# EFM32GG12B390F1024GL112 register map
File version: 3.0.0
CPU: CM4 r0p1, little endian, MPU, FPU, 3 interrupt priority bits
Registers are 32-bit, read-write, reset 0x0 unless marked. A register's access mark holds for its fields unless they carry their own. Offsets are from the block's base; [hi:lo] are bit positions; {n}, {i} and the like mark numbered series.

## QSPI0
Base 0x4001C400
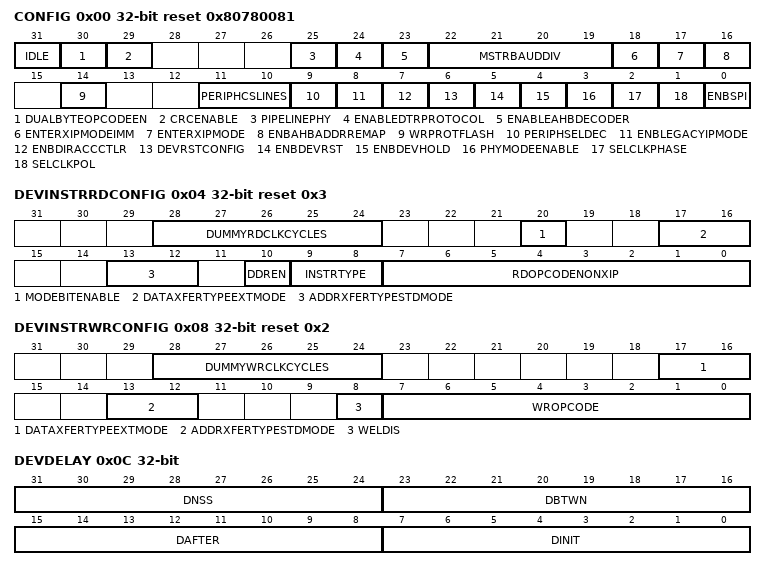
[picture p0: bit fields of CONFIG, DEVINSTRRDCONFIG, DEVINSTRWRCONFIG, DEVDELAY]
0x00 CONFIG reset 0x80780081 — Octal-SPI Configuration Register
  [31] IDLE ro — Serial Interface and Low Level SPI Pipeline is IDLE
  [30] DUALBYTEOPCODEEN — Dual-byte Opcode Mode Enable Bit
  [29] CRCENABLE — CRC Enable Bit
  [25] PIPELINEPHY — Pipeline PHY Mode Enable
  [24] ENABLEDTRPROTOCOL
  [23] ENABLEAHBDECODER — Enable Address Decoder
  [22:19] MSTRBAUDDIV — Master Mode Baud Rate Divisor
  [18] ENTERXIPMODEIMM — Enter XIP Mode Immediately
  [17] ENTERXIPMODE — Enter XIP Mode on Next READ
  [16] ENBAHBADDRREMAP — Enable Address Remapping
  [14] WRPROTFLASH — Write Protect Flash Pin
  [11:10] PERIPHCSLINES — Peripheral Chip Select Lines
  [9] PERIPHSELDEC — Peripheral Select Decode
  [8] ENBLEGACYIPMODE — Legacy IP Mode Enable
  [7] ENBDIRACCCTLR — Enable Direct Access Controller
  [6] DEVRSTCONFIG — Device Reset Configuration
  [5] ENBDEVRST — Enable Device Reset
  [4] ENBDEVHOLD — Enable Device Hold
  [3] PHYMODEENABLE
  [2] SELCLKPHASE — Clock Phase, CPHA
  [1] SELCLKPOL — Clock Polarity, CPOL
  [0] ENBSPI — QSPI Enable
0x04 DEVINSTRRDCONFIG reset 0x3 — Device Read Instruction Configuration Register
  [28:24] DUMMYRDCLKCYCLES — Dummy Read Clock Cycles
  [20] MODEBITENABLE
  [17:16] DATAXFERTYPEEXTMODE — Data Transfer Type for Standard SPI Modes
  [13:12] ADDRXFERTYPESTDMODE — Address Transfer Type for Standard SPI Modes
  [10] DDREN — DDR Enable
  [9:8] INSTRTYPE — Instruction Type
  [7:0] RDOPCODENONXIP — Read Opcode in Non-XIP Mode
0x08 DEVINSTRWRCONFIG reset 0x2 — Device Write Instruction Configuration Register
  [28:24] DUMMYWRCLKCYCLES — Dummy Write Clock Cycles
  [17:16] DATAXFERTYPEEXTMODE — Data Transfer Type for Standard SPI Modes
  [13:12] ADDRXFERTYPESTDMODE — Address Transfer Type for Standard SPI Modes
  [8] WELDIS — WEL Disable
  [7:0] WROPCODE — Write Opcode
0x0C DEVDELAY — Device Delay Register
  [31:24] DNSS — Clock Delay for Chip Select Deassert
  [23:16] DBTWN — Clock Delay Between Two Chip Selects
  [15:8] DAFTER — Clock Delay for Last Transaction Bit
  [7:0] DINIT — Clock Delay for CS
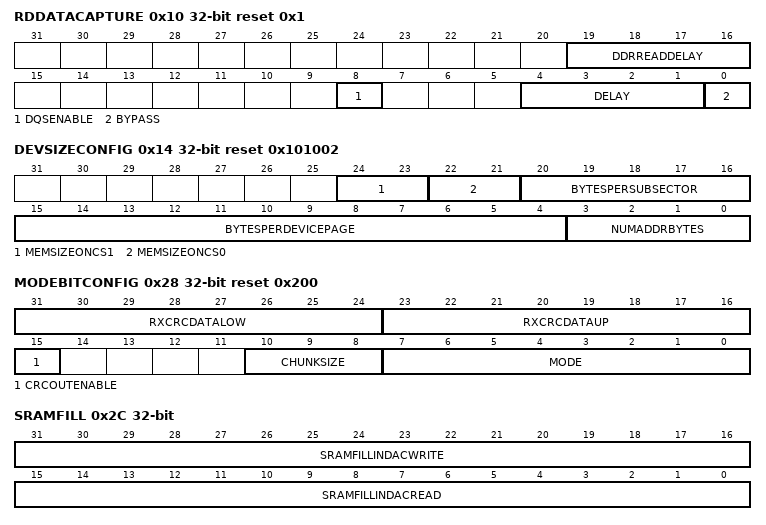
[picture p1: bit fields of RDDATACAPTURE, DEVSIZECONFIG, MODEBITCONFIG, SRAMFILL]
0x10 RDDATACAPTURE reset 0x1 — Read Data Capture Register
  [19:16] DDRREADDELAY
  [8] DQSENABLE — DQS Enable Bit
  [4:1] DELAY — Read Delay
  [0] BYPASS — Bypass the Adapted Loopback Clock Circuit
0x14 DEVSIZECONFIG reset 0x101002 — Device Size Configuration Register
  [24:23] MEMSIZEONCS1 — Size of Flash Device Connected to CS[1] Pin
  [22:21] MEMSIZEONCS0 — Size of Flash Device Connected to CS[0] Pin
  [20:16] BYTESPERSUBSECTOR — Number of Bytes Per Block
  [15:4] BYTESPERDEVICEPAGE — Number of Bytes Per Device Page
  [3:0] NUMADDRBYTES — Number of Address Bytes
0x18 SRAMPARTITIONCFG reset 0x80 — SRAM Partition Configuration Register
  [7:0] ADDR — Indirect Read Partition Size
0x1C INDAHBADDRTRIGGER — Indirect Address Trigger Register
  [31:0] ADDR
0x24 REMAPADDR — Remap Address Register
  [31:0] VALUE — Remap Address Value
0x28 MODEBITCONFIG reset 0x200 — Mode Bit Configuration Register
  [31:24] RXCRCDATALOW ro — RX CRC Data (lower)
  [23:16] RXCRCDATAUP ro — RX CRC Data (upper)
  [15] CRCOUTENABLE — CRC# Output Enable Bit
  [10:8] CHUNKSIZE
  [7:0] MODE — Mode Bits
0x2C SRAMFILL ro
  [31:16] SRAMFILLINDACWRITE — SRAM Fill Level (Indirect Write Partition)
  [15:0] SRAMFILLINDACREAD — SRAM Fill Level (Indirect Read Partition)
0x30 TXTHRESH reset 0x1 — TX Threshold Register
  [4:0] LEVEL — Threshold Level
0x34 RXTHRESH reset 0x1 — RX Threshold Register
  [4:0] LEVEL — Threshold Level
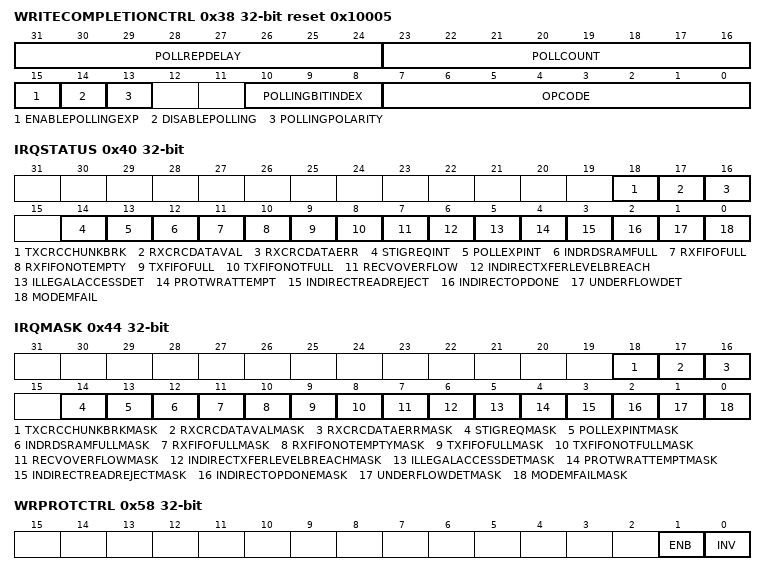
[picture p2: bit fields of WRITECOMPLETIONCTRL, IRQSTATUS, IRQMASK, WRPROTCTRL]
0x38 WRITECOMPLETIONCTRL reset 0x10005 — Write Completion Control Register
  [31:24] POLLREPDELAY — Poll Repetition Delay
  [23:16] POLLCOUNT
  [15] ENABLEPOLLINGEXP — Enable Polling Expiration
  [14] DISABLEPOLLING
  [13] POLLINGPOLARITY
  [10:8] POLLINGBITINDEX
  [7:0] OPCODE
0x3C NOOFPOLLSBEFEXP reset 0xFFFFFFFF — Polling Expiration Register
  [31:0] NOOFPOLLSBEFEXP — Number of Polls Cycles Before Expiration
0x40 IRQSTATUS — Interrupt Status Register
  [18] TXCRCCHUNKBRK — TX CRC Chunk Was Broken
  [17] RXCRCDATAVAL — RX CRC Data Valid
  [16] RXCRCDATAERR — RX CRC Data Error
  [14] STIGREQINT — The Controller is Ready for Getting Another STIG Request
  [13] POLLEXPINT — The Maximum Number of Programmed Polls Cycles is Expired
  [12] INDRDSRAMFULL — Indirect Read Partition Overflow
  [11] RXFIFOFULL — Small RX FIFO Full
  [10] RXFIFONOTEMPTY — Small RX FIFO Not Empty
  [9] TXFIFOFULL — Small TX FIFO Full
  [8] TXFIFONOTFULL — Small TX FIFO Not Full
  [7] RECVOVERFLOW — Receive Overflow
  [6] INDIRECTXFERLEVELBREACH — Indirect Transfer Watermark Level Breached
  [5] ILLEGALACCESSDET — Illegal Memory Access Has Been Detected
  [4] PROTWRATTEMPT — Write to Protected Area Was Attempted and Rejected
  [3] INDIRECTREADREJECT — Indirect Operation Was Requested but Could Not Be Accepted
  [2] INDIRECTOPDONE — Indirect Operation Complete
  [1] UNDERFLOWDET — Underflow Detected
  [0] MODEMFAIL — Mode M Failure
0x44 IRQMASK — Interrupt Mask
  [18] TXCRCCHUNKBRKMASK — TX CRC Chunk Was Broken Mask
  [17] RXCRCDATAVALMASK — RX CRC Data Valid Mask
  [16] RXCRCDATAERRMASK — RX CRC Data Error Mask
  [14] STIGREQMASK — STIG Request Completion Mask
  [13] POLLEXPINTMASK — Polling Expiration Detected Mask
  [12] INDRDSRAMFULLMASK — Indirect Read Partition Overflow Mask
  [11] RXFIFOFULLMASK — Small RX FIFO Full Mask
  [10] RXFIFONOTEMPTYMASK — Small RX FIFO Not Empty Mask
  [9] TXFIFOFULLMASK — Small TX FIFO Full Mask
  [8] TXFIFONOTFULLMASK — Small TX FIFO Not Full Mask
  [7] RECVOVERFLOWMASK — Receive Overflow Mask
  [6] INDIRECTXFERLEVELBREACHMASK — Transfer Watermark Breach Mask
  [5] ILLEGALACCESSDETMASK — Illegal Access Detected Mask
  [4] PROTWRATTEMPTMASK — Protected Area Write Attempt Mask
  [3] INDIRECTREADREJECTMASK
  [2] INDIRECTOPDONEMASK — Indirect Complete Mask
  [1] UNDERFLOWDETMASK — Underflow Detected Mask
  [0] MODEMFAILMASK — Mode M Failure Mask
0x50 LOWERWRPROT — Lower Write Protection Register
  [31:0] SUBSECTOR — Lower Block Number
0x54 UPPERWRPROT — Upper Write Protection Register
  [31:0] SUBSECTOR — Upper Block Number
0x58 WRPROTCTRL — Write Protection Control Register
  [1] ENB — Write Protection Enable Bit
  [0] INV — Write Protection Inversion Bit
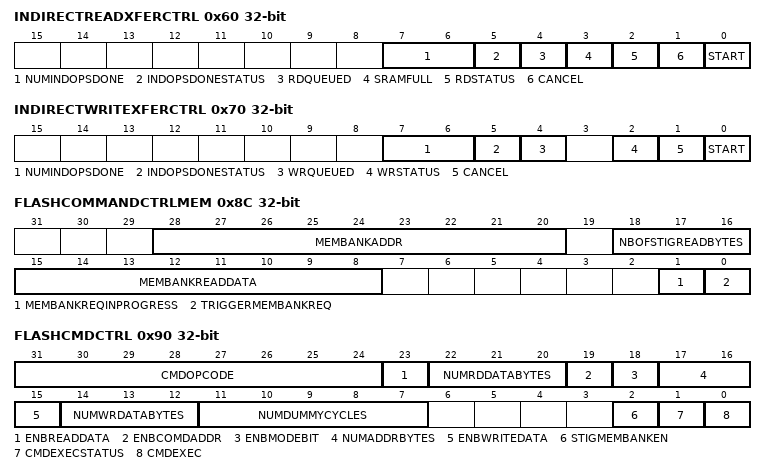
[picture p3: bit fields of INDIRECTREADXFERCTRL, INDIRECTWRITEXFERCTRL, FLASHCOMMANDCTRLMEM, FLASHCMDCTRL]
0x60 INDIRECTREADXFERCTRL — Indirect Read Transfer Control Register
  [7:6] NUMINDOPSDONE ro — Number Indirect Operations Done
  [5] INDOPSDONESTATUS — Indirect Completion Status
  [4] RDQUEUED ro — Two Indirect Read Operations Have Been Queued
  [3] SRAMFULL
  [2] RDSTATUS ro — Indirect Read Status
  [1] CANCEL wo — Cancel Indirect Read
  [0] START wo — Start Indirect Read
0x64 INDIRECTREADXFERWATERMARK — Indirect Read Transfer Watermark Register
  [31:0] LEVEL — Watermark Value
0x68 INDIRECTREADXFERSTART — Indirect Read Transfer Start Address Register
  [31:0] ADDR — Indirect Read Transfer Start Address
0x6C INDIRECTREADXFERNUMBYTES — Indirect Read Transfer Number Bytes Register
  [31:0] VALUE — Indirect Read Transfer Number Bytes
0x70 INDIRECTWRITEXFERCTRL — Indirect Write Transfer Control Register
  [7:6] NUMINDOPSDONE ro — Indirect Operations Done
  [5] INDOPSDONESTATUS — Indirect Completion Status
  [4] WRQUEUED ro — Two Indirect Write Operations Have Been Queued
  [2] WRSTATUS ro — Indirect Write Status
  [1] CANCEL wo — Cancel Indirect Write
  [0] START wo — Start Indirect Write
0x74 INDIRECTWRITEXFERWATERMARK reset 0xFFFFFFFF — Indirect Write Transfer Watermark Register
  [31:0] LEVEL — Watermark Value
0x78 INDIRECTWRITEXFERSTART — Indirect Write Transfer Start Address Register
  [31:0] ADDR — Start of Indirect Access
0x7C INDIRECTWRITEXFERNUMBYTES — Indirect Write Transfer Number Bytes Register
  [31:0] VALUE — Indirect Number of Bytes
0x80 INDIRECTTRIGGERADDRRANGE reset 0x4 — Indirect Trigger Address Range Register
  [3:0] INDRANGEWIDTH — Indirect Trigger Address Width
0x8C FLASHCOMMANDCTRLMEM — Flash Command Control Memory Register (STIG)
  [28:20] MEMBANKADDR — Memory Bank Address
  [18:16] NBOFSTIGREADBYTES — Number of Read Bytes for the Extended STIG
  [15:8] MEMBANKREADDATA ro — Last Requested Data From the STIG Memory Bank
  [1] MEMBANKREQINPROGRESS ro — Memory Bank Data Request in Progress
  [0] TRIGGERMEMBANKREQ wo — Trigger the Memory Bank Data Request
0x90 FLASHCMDCTRL — Flash Command Control Register (STIG)
  [31:24] CMDOPCODE — Command Opcode
  [23] ENBREADDATA — Read Data Enable
  [22:20] NUMRDDATABYTES — Number of Read Data Bytes
  [19] ENBCOMDADDR — Command Address Enable
  [18] ENBMODEBIT — Mode Bit Enable
  [17:16] NUMADDRBYTES — Number of Address Bytes
  [15] ENBWRITEDATA — Write Data Enable
  [14:12] NUMWRDATABYTES — Number of Write Data Bytes
  [11:7] NUMDUMMYCYCLES — Number of Dummy Cycles
  [2] STIGMEMBANKEN — STIG Memory Bank Enable Bit
  [1] CMDEXECSTATUS ro — Command Execution in Progress
  [0] CMDEXEC wo — Execute the Command
0x94 FLASHCMDADDR — Flash Command Address Register (STIG)
  [31:0] ADDR — Command Address
0xA0 FLASHRDDATALOWER ro — Flash Command Read Data Register (Lower) (STIG)
  [31:0] DATA — Read Data Lower
0xA4 FLASHRDDATAUPPER ro — Flash Command Read Data Register (Upper) (STIG)
  [31:0] DATA — Read Data Upper
0xA8 FLASHWRDATALOWER — Flash Command Write Data Register (Lower) (STIG)
  [31:0] DATA — Command Write Data Lower Byte
0xAC FLASHWRDATAUPPER — Flash Command Write Data Register (Upper) (STIG)
  [31:0] DATA — Command Write Data Upper Byte
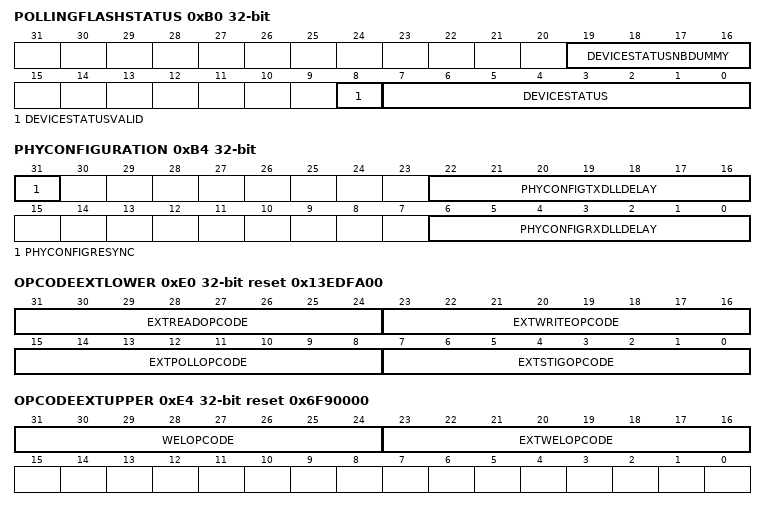
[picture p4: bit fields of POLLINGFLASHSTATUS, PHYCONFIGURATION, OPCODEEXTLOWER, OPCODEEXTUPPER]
0xB0 POLLINGFLASHSTATUS
  [19:16] DEVICESTATUSNBDUMMY — Auto-polling Dummy Cycles
  [8] DEVICESTATUSVALID ro
  [7:0] DEVICESTATUS ro
0xB4 PHYCONFIGURATION
  [31] PHYCONFIGRESYNC wo
  [22:16] PHYCONFIGTXDLLDELAY — TX DLL Delay
  [6:0] PHYCONFIGRXDLLDELAY — RX DLL Delay
0xE0 OPCODEEXTLOWER reset 0x13EDFA00 — Opcode Extension Register (Lower)
  [31:24] EXTREADOPCODE — Read Opcode Extension
  [23:16] EXTWRITEOPCODE — Write Opcode Extension
  [15:8] EXTPOLLOPCODE — Polling Opcode Extension
  [7:0] EXTSTIGOPCODE — STIG Opcode Extension
0xE4 OPCODEEXTUPPER reset 0x6F90000 — Opcode Extension Register (Upper)
  [31:24] WELOPCODE
  [23:16] EXTWELOPCODE — WEL Opcode Extension
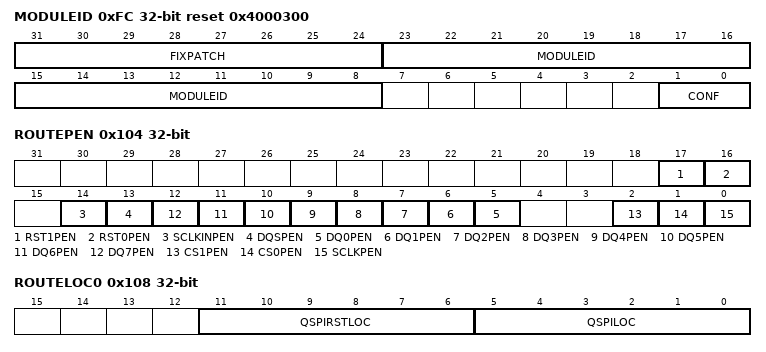
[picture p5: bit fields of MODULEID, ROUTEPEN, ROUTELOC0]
0xFC MODULEID ro reset 0x4000300
  [31:24] FIXPATCH — Fix/patch Number
  [23:8] MODULEID — Module/Revision ID Number
  [1:0] CONF — Configuration ID Number
0x104 ROUTEPEN — I/O Routing Pin Enable Register
  [17] RST1PEN — RST1 Pin Enable
  [16] RST0PEN — RST0 Pin Enable
  [14] SCLKINPEN — SCLKIN Pin Enable
  [13] DQSPEN — DQS Pin Enable
  [n+5] DQ{n}PEN (n=0..7) — DQ{n} Pin Enable
  [2] CS1PEN — CS1 Pin Enable
  [1] CS0PEN — CS0 Pin Enable
  [0] SCLKPEN — SCLK Pin Enable
0x108 ROUTELOC0 — I/O Route Location Register 0
  [11:6] QSPIRSTLOC — I/O Location
    0=LOC0 (Location 0); 1=LOC1 (Location 1)
  [5:0] QSPILOC — I/O Location
    0=LOC0 (Location 0); 1=LOC1 (Location 1)

## Notices in the file
# License
Copyright 2020 Silicon Laboratories Inc. www.silabs.com
SPDX-License-Identifier: Zlib
The licensor of this software is Silicon Laboratories Inc.
This software is provided 'as-is', without any express or implied
warranty. In no event will the authors be held liable for any damages
arising from the use of this software.
Permission is granted to anyone to use this software for any purpose,
including commercial applications, and to alter it and redistribute it
freely, subject to the following restrictions:
1. The origin of this software must not be misrepresented; you must not
claim that you wrote the original software. If you use this software
in a product, an acknowledgment in the product documentation would be
appreciated but is not required.
2. Altered source versions must be plainly marked as such, and must not be
misrepresented as being the original software.
3. This notice may not be removed or altered from any source distribution.
